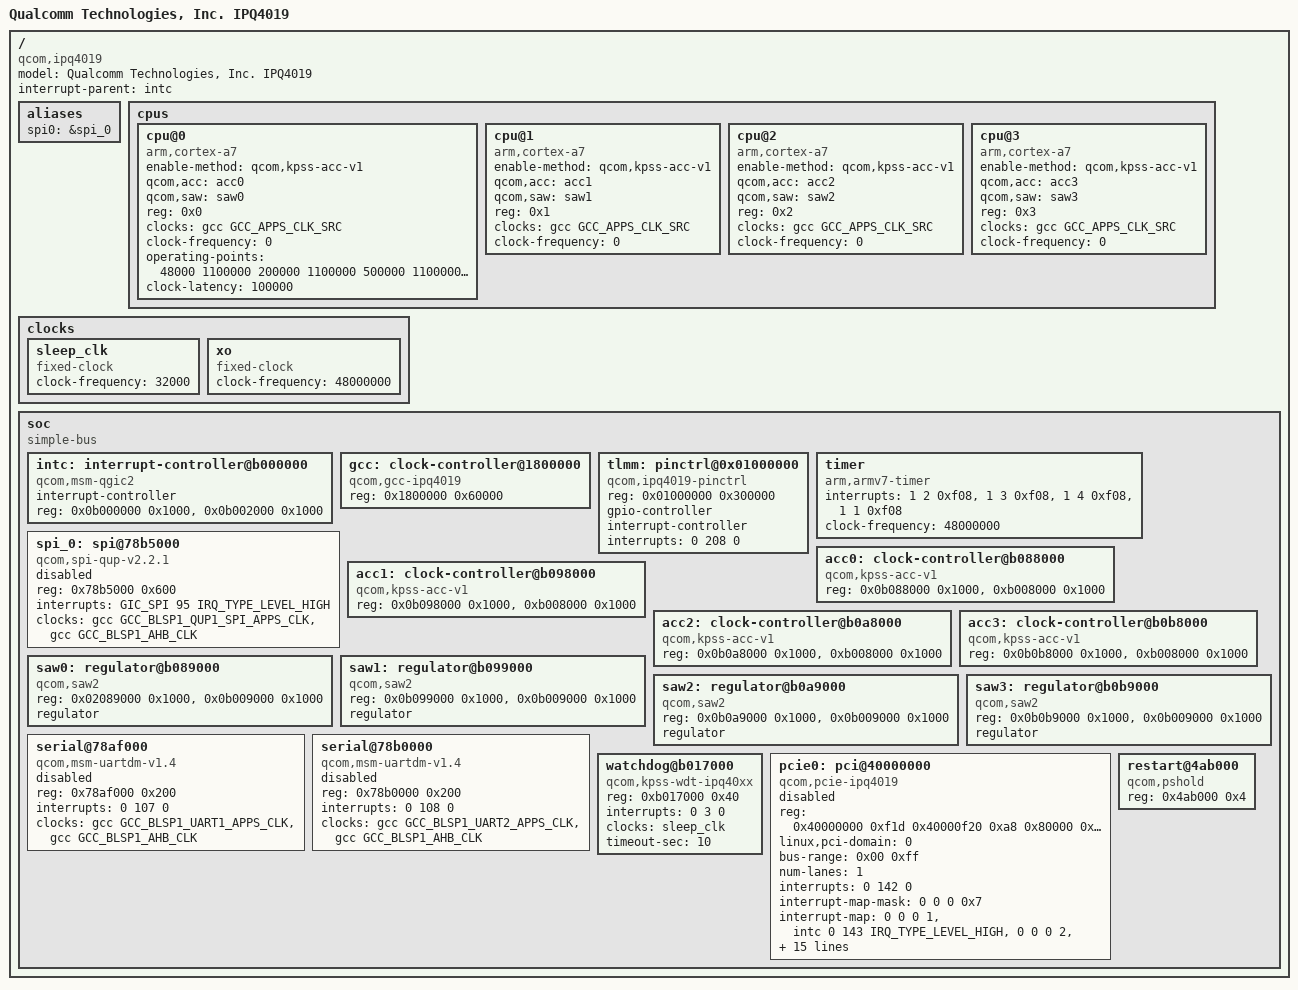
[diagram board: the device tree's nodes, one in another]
/*
 * Copyright (c) 2015 - 2016, The Linux Foundation. All rights reserved.
 *
 * Permission to use, copy, modify, and/or distribute this software for any
 * purpose with or without fee is hereby granted, provided that the above
 * copyright notice and this permission notice appear in all copies.
 *
 * THE SOFTWARE IS PROVIDED "AS IS" AND THE AUTHOR DISCLAIMS ALL WARRANTIES
 * WITH REGARD TO THIS SOFTWARE INCLUDING ALL IMPLIED WARRANTIES OF
 * MERCHANTABILITY AND FITNESS. IN NO EVENT SHALL THE AUTHOR BE LIABLE FOR
 * ANY SPECIAL, DIRECT, INDIRECT, OR CONSEQUENTIAL DAMAGES OR ANY DAMAGES
 * WHATSOEVER RESULTING FROM LOSS OF USE, DATA OR PROFITS, WHETHER IN AN
 * ACTION OF CONTRACT, NEGLIGENCE OR OTHER TORTIOUS ACTION, ARISING OUT OF
 * OR IN CONNECTION WITH THE USE OR PERFORMANCE OF THIS SOFTWARE.
 */

/dts-v1/;

#include "skeleton.dtsi"
#include <dt-bindings/clock/qcom,gcc-ipq4019.h>
#include <dt-bindings/interrupt-controller/arm-gic.h>
#include <dt-bindings/interrupt-controller/irq.h>

/ {
	model = "Qualcomm Technologies, Inc. IPQ4019";
	compatible = "qcom,ipq4019";
	interrupt-parent = <&intc>;

	aliases {
		spi0 = &spi_0;
	};

	cpus {
		#address-cells = <1>;
		#size-cells = <0>;
		cpu@0 {
			device_type = "cpu";
			compatible = "arm,cortex-a7";
			enable-method = "qcom,kpss-acc-v1";
			qcom,acc = <&acc0>;
			qcom,saw = <&saw0>;
			reg = <0x0>;
			clocks = <&gcc GCC_APPS_CLK_SRC>;
			clock-frequency = <0>;
			operating-points = <
				/* kHz	uV (fixed) */
				48000	1100000
				200000	1100000
				500000	1100000
				666000	1100000
			>;
			clock-latency = <100000>;
		};

		cpu@1 {
			device_type = "cpu";
			compatible = "arm,cortex-a7";
			enable-method = "qcom,kpss-acc-v1";
			qcom,acc = <&acc1>;
			qcom,saw = <&saw1>;
			reg = <0x1>;
			clocks = <&gcc GCC_APPS_CLK_SRC>;
			clock-frequency = <0>;
		};

		cpu@2 {
			device_type = "cpu";
			compatible = "arm,cortex-a7";
			enable-method = "qcom,kpss-acc-v1";
			qcom,acc = <&acc2>;
			qcom,saw = <&saw2>;
			reg = <0x2>;
			clocks = <&gcc GCC_APPS_CLK_SRC>;
			clock-frequency = <0>;
		};

		cpu@3 {
			device_type = "cpu";
			compatible = "arm,cortex-a7";
			enable-method = "qcom,kpss-acc-v1";
			qcom,acc = <&acc3>;
			qcom,saw = <&saw3>;
			reg = <0x3>;
			clocks = <&gcc GCC_APPS_CLK_SRC>;
			clock-frequency = <0>;
		};
	};

	clocks {
		sleep_clk: sleep_clk {
			compatible = "fixed-clock";
			clock-frequency = <32000>;
			#clock-cells = <0>;
		};
		xo: xo {
			compatible = "fixed-clock";
			clock-frequency = <48000000>;
			#clock-cells = <0>;
		};
	};

	soc {
		#address-cells = <1>;
		#size-cells = <1>;
		ranges;
		compatible = "simple-bus";

		intc: interrupt-controller@b000000 {
			compatible = "qcom,msm-qgic2";
			interrupt-controller;
			#interrupt-cells = <3>;
			reg = <0x0b000000 0x1000>,
			<0x0b002000 0x1000>;
		};

		gcc: clock-controller@1800000 {
			compatible = "qcom,gcc-ipq4019";
			#clock-cells = <1>;
			#reset-cells = <1>;
			reg = <0x1800000 0x60000>;
		};

		tlmm: pinctrl@0x01000000 {
			compatible = "qcom,ipq4019-pinctrl";
			reg = <0x01000000 0x300000>;
			gpio-controller;
			#gpio-cells = <2>;
			interrupt-controller;
			#interrupt-cells = <2>;
			interrupts = <0 208 0>;
		};

		timer {
			compatible = "arm,armv7-timer";
			interrupts = <1 2 0xf08>,
				     <1 3 0xf08>,
				     <1 4 0xf08>,
				     <1 1 0xf08>;
			clock-frequency = <48000000>;
		};

		spi_0: spi@78b5000 {
			compatible = "qcom,spi-qup-v2.2.1";
			reg = <0x78b5000 0x600>;
			interrupts = <GIC_SPI 95 IRQ_TYPE_LEVEL_HIGH>;
			clocks = <&gcc GCC_BLSP1_QUP1_SPI_APPS_CLK>,
				 <&gcc GCC_BLSP1_AHB_CLK>;
			clock-names = "core", "iface";
			#address-cells = <1>;
			#size-cells = <0>;
			status = "disabled";
		};

		acc0: clock-controller@b088000 {
			compatible = "qcom,kpss-acc-v1";
			reg = <0x0b088000 0x1000>, <0xb008000 0x1000>;
		};

		acc1: clock-controller@b098000 {
			compatible = "qcom,kpss-acc-v1";
			reg = <0x0b098000 0x1000>, <0xb008000 0x1000>;
		};

		acc2: clock-controller@b0a8000 {
			compatible = "qcom,kpss-acc-v1";
			reg = <0x0b0a8000 0x1000>, <0xb008000 0x1000>;
		};

		acc3: clock-controller@b0b8000 {
			compatible = "qcom,kpss-acc-v1";
			reg = <0x0b0b8000 0x1000>, <0xb008000 0x1000>;
		};

		saw0: regulator@b089000 {
			compatible = "qcom,saw2";
			reg = <0x02089000 0x1000>, <0x0b009000 0x1000>;
			regulator;
		};

		saw1: regulator@b099000 {
			compatible = "qcom,saw2";
			reg = <0x0b099000 0x1000>, <0x0b009000 0x1000>;
			regulator;
		};

		saw2: regulator@b0a9000 {
			compatible = "qcom,saw2";
			reg = <0x0b0a9000 0x1000>, <0x0b009000 0x1000>;
			regulator;
		};

		saw3: regulator@b0b9000 {
			compatible = "qcom,saw2";
			reg = <0x0b0b9000 0x1000>, <0x0b009000 0x1000>;
			regulator;
		};

		serial@78af000 {
			compatible = "qcom,msm-uartdm-v1.4", "qcom,msm-uartdm";
			reg = <0x78af000 0x200>;
			interrupts = <0 107 0>;
			status = "disabled";
			clocks = <&gcc GCC_BLSP1_UART1_APPS_CLK>,
				<&gcc GCC_BLSP1_AHB_CLK>;
			clock-names = "core", "iface";
		};

		serial@78b0000 {
			compatible = "qcom,msm-uartdm-v1.4", "qcom,msm-uartdm";
			reg = <0x78b0000 0x200>;
			interrupts = <0 108 0>;
			status = "disabled";
			clocks = <&gcc GCC_BLSP1_UART2_APPS_CLK>,
				<&gcc GCC_BLSP1_AHB_CLK>;
			clock-names = "core", "iface";
		};

		watchdog@b017000 {
			compatible = "qcom,kpss-wdt-ipq40xx";
			reg = <0xb017000 0x40>;
			interrupt-names = "bark_irq";
			interrupts = <0 3 0>;
			clocks = <&sleep_clk>;
			timeout-sec = <10>;
			status = "ok";
		};

		pcie0: pci@40000000 {
			compatible = "qcom,pcie-ipq4019";
			reg =  <0x40000000 0xf1d
				0x40000f20 0xa8
				0x80000 0x2000
				0x40100000 0x1000>;
			reg-names = "dbi", "elbi", "parf", "config";
			device_type = "pci";
			linux,pci-domain = <0>;
			bus-range = <0x00 0xff>;
			num-lanes = <1>;
			#address-cells = <3>;
			#size-cells = <2>;

			ranges = <0x81000000 0 0x40200000 0x40200000
				  0 0x00100000   /* downstream I/O */
				  0x82000000 0 0x40300000 0x40300000
				  0 0x00d00000>; /* non-prefetchable memory */

			interrupts = <0 142 0>;
			interrupt-names = "msi";
			#interrupt-cells = <1>;
			interrupt-map-mask = <0 0 0 0x7>;
			interrupt-map = <0 0 0 1 &intc 0 143
					 IRQ_TYPE_LEVEL_HIGH>, /* int_a */
					<0 0 0 2 &intc 0 144
					 IRQ_TYPE_LEVEL_HIGH>, /* int_b */
					<0 0 0 3 &intc 0 145
					 IRQ_TYPE_LEVEL_HIGH>, /* int_c */
					<0 0 0 4 &intc 0 146
					 IRQ_TYPE_LEVEL_HIGH>; /* int_d */
			clocks = <&gcc GCC_PCIE_AHB_CLK>,
				 <&gcc GCC_PCIE_AXI_M_CLK>,
				 <&gcc GCC_PCIE_AXI_S_CLK>;
			clock-names = "ahb",
				      "axi_m",
				      "axi_s";

			resets = <&gcc PCIE_AXI_M_ARES>,
				 <&gcc PCIE_AXI_S_ARES>,
				 <&gcc PCIE_PIPE_ARES>,
				 <&gcc PCIE_AXI_M_VMIDMT_ARES>,
				 <&gcc PCIE_AXI_S_XPU_ARES>,
				 <&gcc PCIE_PARF_XPU_ARES>,
				 <&gcc PCIE_PHY_ARES>,
				 <&gcc PCIE_AXI_M_STICKY_ARES>,
				 <&gcc PCIE_PIPE_STICKY_ARES>,
				 <&gcc PCIE_PWR_ARES>,
				 <&gcc PCIE_AHB_ARES>,
				 <&gcc PCIE_PHY_AHB_ARES>;
			reset-names = "axi_m",
				      "axi_s",
				      "pipe",
				      "axi_m_vmid",
				      "axi_s_xpu",
				      "parf",
				      "phy",
				      "axi_m_sticky",
				      "pipe_sticky",
				      "pwr",
				      "ahb",
				      "phy_ahb";

			status = "disabled";
		};

		restart@4ab000 {
			compatible = "qcom,pshold";
			reg = <0x4ab000 0x4>;
		};
	};
};
